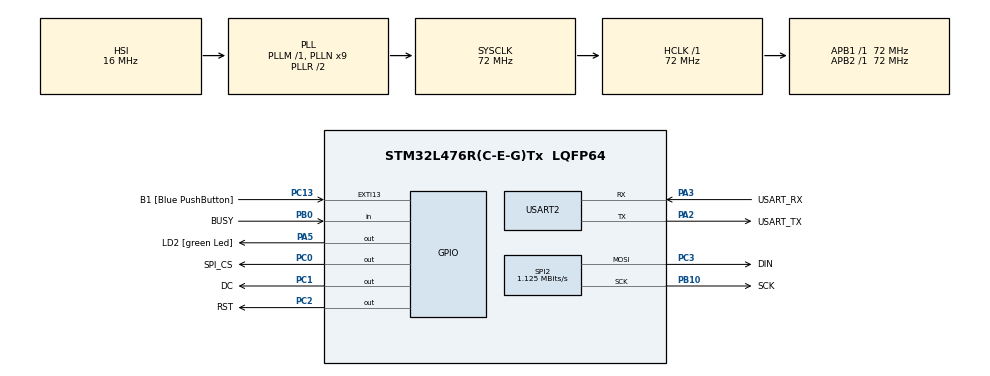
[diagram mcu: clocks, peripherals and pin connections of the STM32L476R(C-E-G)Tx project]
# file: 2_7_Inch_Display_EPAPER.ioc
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Dma.Request0=SPI2_TX
Dma.SPI2_TX.0.Direction=DMA_MEMORY_TO_PERIPH
Dma.SPI2_TX.0.Instance=DMA1_Channel5
Dma.SPI2_TX.0.MemDataAlignment=DMA_MDATAALIGN_BYTE
Dma.SPI2_TX.0.MemInc=DMA_MINC_ENABLE
Dma.SPI2_TX.0.Mode=DMA_NORMAL
Dma.SPI2_TX.0.PeriphDataAlignment=DMA_PDATAALIGN_BYTE
Dma.SPI2_TX.0.PeriphInc=DMA_PINC_DISABLE
Dma.SPI2_TX.0.Priority=DMA_PRIORITY_HIGH
FREERTOS.Tasks01=defaultTask,-2,128,StartDefaultTask,Default,NULL,Dynamic,NULL,NULL;change_machine_state_task,0,256,Start_change_machine_state_task,Default,NULL,Dynamic,NULL,NULL;display_driver_task,0,2048,Start_display_driver_task,Default,NULL,Dynamic,NULL,NULL
FREERTOS.configMAX_TASK_NAME_LEN=100
FREERTOS.configTOTAL_HEAP_SIZE=40960
FREERTOS.configUSE_NEWLIB_REENTRANT=1
Mcu.Family=STM32L4
Mcu.Name=STM32L476R(C-E-G)Tx
Mcu.Package=LQFP64
NVIC.DMA1_Channel5_IRQn=true\:5\:0\:false\:false\:true\:true\:false\:true\:true
NVIC.PriorityGroup=NVIC_PRIORITYGROUP_4
NVIC.TIM6_DAC_IRQn=true\:15\:0\:false\:false\:true\:false\:false\:true\:true
NVIC.TimeBase=TIM6_DAC_IRQn
NVIC.TimeBaseIP=TIM6
PA13\ (JTMS-SWDIO).GPIO_Label=TMS
PA13\ (JTMS-SWDIO).Mode=Serial_Wire
PA13\ (JTMS-SWDIO).Signal=SYS_JTMS-SWDIO
PA14\ (JTCK-SWCLK).GPIO_Label=TCK
PA14\ (JTCK-SWCLK).Mode=Serial_Wire
PA14\ (JTCK-SWCLK).Signal=SYS_JTCK-SWCLK
PA2.GPIO_Label=USART_TX
PA2.GPIO_Mode=GPIO_MODE_AF_PP
PA2.GPIO_PuPd=GPIO_NOPULL
PA2.GPIO_Speed=GPIO_SPEED_FREQ_VERY_HIGH
PA2.Mode=Asynchronous
PA2.Signal=USART2_TX
PA3.GPIO_Label=USART_RX
PA3.GPIO_Mode=GPIO_MODE_AF_PP
PA3.GPIO_PuPd=GPIO_NOPULL
PA3.GPIO_Speed=GPIO_SPEED_FREQ_VERY_HIGH
PA3.Mode=Asynchronous
PA3.Signal=USART2_RX
PA5.GPIO_Label=LD2 [green Led]
PA5.GPIO_ModeDefaultOutputPP=GPIO_MODE_OUTPUT_PP
PA5.GPIO_PuPd=GPIO_NOPULL
PA5.GPIO_Speed=GPIO_SPEED_FREQ_LOW
PA5.Signal=GPIO_Output
PB0.GPIO_Label=BUSY
PB0.GPIO_PuPd=GPIO_NOPULL
PB0.Signal=GPIO_Input
PB10.GPIO_Label=SCK
PB10.GPIO_Mode=GPIO_MODE_AF_PP
PB10.GPIO_Speed=GPIO_SPEED_FREQ_HIGH
PB10.Mode=TX_Only_Simplex_Unidirect_Master
PB10.Signal=SPI2_SCK
PB3\ (JTDO-TRACESWO).GPIO_Label=SWO
PB3\ (JTDO-TRACESWO).Signal=SYS_JTDO-SWO
PC0.GPIO_Label=SPI_CS
PC0.GPIO_PuPd=GPIO_PULLUP
PC0.GPIO_Speed=GPIO_SPEED_FREQ_LOW
PC0.Signal=GPIO_Output
PC1.GPIO_Label=DC
PC1.GPIO_PuPd=GPIO_PULLUP
PC1.GPIO_Speed=GPIO_SPEED_FREQ_LOW
PC1.Signal=GPIO_Output
PC13.GPIO_Label=B1 [Blue PushButton]
PC13.GPIO_ModeDefaultEXTI=GPIO_MODE_IT_FALLING
PC13.GPIO_PuPd=GPIO_NOPULL
PC13.Signal=GPXTI13
PC14-OSC32_IN\ (PC14).Mode=LSE-External-Oscillator
PC14-OSC32_IN\ (PC14).Signal=RCC_OSC32_IN
PC15-OSC32_OUT\ (PC15).Mode=LSE-External-Oscillator
PC15-OSC32_OUT\ (PC15).Signal=RCC_OSC32_OUT
PC2.GPIO_Label=RST
PC2.GPIO_PuPd=GPIO_PULLUP
PC2.GPIO_Speed=GPIO_SPEED_FREQ_LOW
PC2.Signal=GPIO_Output
PC3.GPIO_Label=DIN
PC3.GPIO_Speed=GPIO_SPEED_FREQ_HIGH
PC3.Mode=TX_Only_Simplex_Unidirect_Master
PC3.Signal=SPI2_MOSI
PH0-OSC_IN\ (PH0).Signal=RCC_OSC_IN
PH1-OSC_OUT\ (PH1).Signal=RCC_OSC_OUT
ProjectManager.HeapSize=0x200
ProjectManager.StackSize=0x400
ProjectManager.TargetToolchain=STM32CubeIDE
RCC.ADCFreq_Value=64000000
RCC.AHBFreq_Value=72000000
RCC.APB1Freq_Value=72000000
RCC.APB1TimFreq_Value=72000000
RCC.APB2Freq_Value=72000000
RCC.APB2TimFreq_Value=72000000
RCC.CortexFreq_Value=72000000
RCC.HCLKFreq_Value=72000000
RCC.HSE_VALUE=8000000
RCC.HSI_VALUE=16000000
RCC.MSI_VALUE=4000000
RCC.PLLN=9
RCC.PLLSourceVirtual=RCC_PLLSOURCE_HSI
RCC.PREFETCH_ENABLE=1
RCC.SYSCLKFreq_VALUE=72000000
RCC.SYSCLKSource=RCC_SYSCLKSOURCE_PLLCLK
RCC.USBFreq_Value=64000000
RCC.VCOOutputFreq_Value=144000000
SPI2.BaudRatePrescaler=SPI_BAUDRATEPRESCALER_64
SPI2.CalculateBaudRate=1.125 MBits/s
SPI2.DataSize=SPI_DATASIZE_8BIT
SPI2.Direction=SPI_DIRECTION_2LINES
SPI2.Mode=SPI_MODE_MASTER
SPI2.VirtualType=VM_MASTER
USART2.VirtualMode-Asynchronous=VM_ASYNC
VP_FREERTOS_VS_CMSIS_V1.Mode=CMSIS_V1
VP_SYS_VS_tim6.Mode=TIM6
board=NUCLEO-L476RG

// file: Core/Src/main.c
/* USER CODE BEGIN Header */
/**
  ******************************************************************************
  * @file           : main.c
  * @brief          : Main program body
  ******************************************************************************
  * @attention
  *
  * Copyright (c) 2024 STMicroelectronics.
  * All rights reserved.
  *
  * This software is licensed under terms that can be found in the LICENSE file
  * in the root directory of this software component.
  * If no LICENSE file comes with this software, it is provided AS-IS.
  *
  ******************************************************************************
  */
/* USER CODE END Header */
#include "main.h"
#include "cmsis_os.h"
#include "dma.h"
#include "spi.h"
#include "usart.h"
#include "gpio.h"

/* USER CODE BEGIN Includes */

#include "Examples/EPD_Test.h"
//#include "QRLib/qr_encode.h"
#include "Logic_controller/EPD_Display_controller.h"

/* USER CODE END Includes */

void SystemClock_Config(void);
void MX_FREERTOS_Init(void);

int main(void)
{
  /* USER CODE BEGIN 1 */

	// Test commit

  /* USER CODE END 1 */

  /* MCU Configuration--------------------------------------------------------*/

  /* Reset of all peripherals, Initializes the Flash interface and the Systick. */
  HAL_Init();

  /* Configure the system clock */
  SystemClock_Config();

  /* Initialize all configured peripherals */
  MX_GPIO_Init();
  MX_DMA_Init();
  MX_USART2_UART_Init();
  MX_SPI2_Init();
  /* USER CODE BEGIN 2 */

  EPD_init();

  EPD_init_states_machine();

  //EPD_Draw_Enter_PIN_Screen();

  //EPD_test();

  /* USER CODE END 2 */

  /* Call init function for freertos objects (in freertos.c) */
  MX_FREERTOS_Init();

  /* Start scheduler */
  osKernelStart();

  /* We should never get here as control is now taken by the scheduler */
  /* Infinite loop */
  while (1)
  {

    /* USER CODE BEGIN 3 */

//	  EPD_change_state();
//	  EPD_Draw_Screen();

  }
  /* USER CODE END 3 */
}

void SystemClock_Config(void)
{
  RCC_OscInitTypeDef RCC_OscInitStruct = {0};
  RCC_ClkInitTypeDef RCC_ClkInitStruct = {0};

  /** Configure the main internal regulator output voltage
  */
  if (HAL_PWREx_ControlVoltageScaling(PWR_REGULATOR_VOLTAGE_SCALE1) != HAL_OK)
  {
    Error_Handler();
  }

  /** Initializes the RCC Oscillators according to the specified parameters
  * in the RCC_OscInitTypeDef structure.
  */
  RCC_OscInitStruct.OscillatorType = RCC_OSCILLATORTYPE_HSI;
  RCC_OscInitStruct.HSIState = RCC_HSI_ON;
  RCC_OscInitStruct.HSICalibrationValue = RCC_HSICALIBRATION_DEFAULT;
  RCC_OscInitStruct.PLL.PLLState = RCC_PLL_ON;
  RCC_OscInitStruct.PLL.PLLSource = RCC_PLLSOURCE_HSI;
  RCC_OscInitStruct.PLL.PLLM = 1;
  RCC_OscInitStruct.PLL.PLLN = 9;
  RCC_OscInitStruct.PLL.PLLP = RCC_PLLP_DIV7;
  RCC_OscInitStruct.PLL.PLLQ = RCC_PLLQ_DIV2;
  RCC_OscInitStruct.PLL.PLLR = RCC_PLLR_DIV2;
  if (HAL_RCC_OscConfig(&RCC_OscInitStruct) != HAL_OK)
  {
    Error_Handler();
  }

  /** Initializes the CPU, AHB and APB buses clocks
  */
  RCC_ClkInitStruct.ClockType = RCC_CLOCKTYPE_HCLK|RCC_CLOCKTYPE_SYSCLK
                              |RCC_CLOCKTYPE_PCLK1|RCC_CLOCKTYPE_PCLK2;
  RCC_ClkInitStruct.SYSCLKSource = RCC_SYSCLKSOURCE_PLLCLK;
  RCC_ClkInitStruct.AHBCLKDivider = RCC_SYSCLK_DIV1;
  RCC_ClkInitStruct.APB1CLKDivider = RCC_HCLK_DIV1;
  RCC_ClkInitStruct.APB2CLKDivider = RCC_HCLK_DIV1;

  if (HAL_RCC_ClockConfig(&RCC_ClkInitStruct, FLASH_LATENCY_4) != HAL_OK)
  {
    Error_Handler();
  }
}

void HAL_TIM_PeriodElapsedCallback(TIM_HandleTypeDef *htim)
{
  if (htim->Instance == TIM6) {
    HAL_IncTick();
  }
}

void Error_Handler(void)
{
  __disable_irq();
  while (1)
  {
  }
}

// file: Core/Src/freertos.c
/* USER CODE BEGIN Header */
/**
  ******************************************************************************
  * File Name          : freertos.c
  * Description        : Code for freertos applications
  ******************************************************************************
  * @attention
  *
  * Copyright (c) 2024 STMicroelectronics.
  * All rights reserved.
  *
  * This software is licensed under terms that can be found in the LICENSE file
  * in the root directory of this software component.
  * If no LICENSE file comes with this software, it is provided AS-IS.
  *
  ******************************************************************************
  */
/* USER CODE END Header */

#include "FreeRTOS.h"
#include "task.h"
#include "main.h"
#include "cmsis_os.h"

/* USER CODE BEGIN Includes */

#include "Examples/EPD_Test.h"
#include "Logic_controller/EPD_Display_controller.h"

/* USER CODE END Includes */

osThreadId defaultTaskHandle;
osThreadId change_machine_state_taskHandle;
osThreadId display_driver_taskHandle;

void StartDefaultTask(void const * argument);
void Start_change_machine_state_task(void const * argument);
void Start_display_driver_task(void const * argument);

void MX_FREERTOS_Init(void); /* (MISRA C 2004 rule 8.1) */

/* GetIdleTaskMemory prototype (linked to static allocation support) */
void vApplicationGetIdleTaskMemory( StaticTask_t **ppxIdleTaskTCBBuffer, StackType_t **ppxIdleTaskStackBuffer, uint32_t *pulIdleTaskStackSize );

/* USER CODE BEGIN GET_IDLE_TASK_MEMORY */
static StaticTask_t xIdleTaskTCBBuffer;
static StackType_t xIdleStack[configMINIMAL_STACK_SIZE];

void vApplicationGetIdleTaskMemory( StaticTask_t **ppxIdleTaskTCBBuffer, StackType_t **ppxIdleTaskStackBuffer, uint32_t *pulIdleTaskStackSize )
{
  *ppxIdleTaskTCBBuffer = &xIdleTaskTCBBuffer;
  *ppxIdleTaskStackBuffer = &xIdleStack[0];
  *pulIdleTaskStackSize = configMINIMAL_STACK_SIZE;
  /* place for user code */
}
/* USER CODE END GET_IDLE_TASK_MEMORY */

void MX_FREERTOS_Init(void) {

  /* Create the thread(s) */
  /* definition and creation of defaultTask */
  osThreadDef(defaultTask, StartDefaultTask, osPriorityLow, 0, 128);
  defaultTaskHandle = osThreadCreate(osThread(defaultTask), NULL);

  /* definition and creation of change_machine_state_task */
  osThreadDef(change_machine_state_task, Start_change_machine_state_task, osPriorityNormal, 0, 256);
  change_machine_state_taskHandle = osThreadCreate(osThread(change_machine_state_task), NULL);

  /* definition and creation of display_driver_task */
  osThreadDef(display_driver_task, Start_display_driver_task, osPriorityNormal, 0, 2048);
  display_driver_taskHandle = osThreadCreate(osThread(display_driver_task), NULL);

}

void StartDefaultTask(void const * argument)
{
  for(;;)
  {
    osDelay(1);
  }
}

void Start_change_machine_state_task(void const * argument)
{
  /* USER CODE BEGIN Start_change_machine_state_task */
  /* Infinite loop */
  for(;;)
  {
	  EPD_change_state();
	  osDelay(1);
  }
  /* USER CODE END Start_change_machine_state_task */
}

void Start_display_driver_task(void const * argument)
{
  /* USER CODE BEGIN Start_display_driver_task */
  /* Infinite loop */
  for(;;)
  {
	  EPD_Draw_Screen();
	  osDelay(1);
  }
  /* USER CODE END Start_display_driver_task */
}
